# ATSAMA5D27 register map
Vendor: Microchip Technology Inc.; File version: 1.0
CPU: CA5 r0p1, little endian, no MPU, no FPU, 4 interrupt priority bits
Address unit: 32 bits
Registers are 32-bit, read-write, reset 0x0 unless marked. A register's access mark holds for its fields unless they carry their own. Offsets are from the block's base; [hi:lo] are bit positions.

## SDMMC0 — Secure Digital MultiMedia Card Controller
Base 0xA0000000
Same registers: SDMMC1 0xB0000000
0x00 SSAR — SDMA System Address / Argument 2 Register
  [31:0] ADDR — SDMA System Address
  [31:0] ARG2 — Argument 2
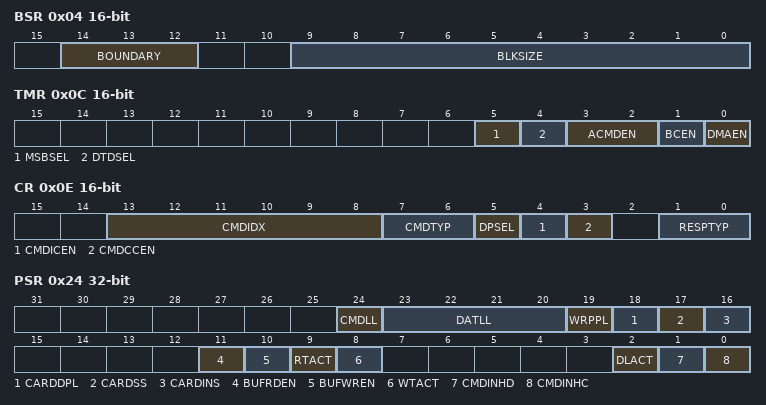
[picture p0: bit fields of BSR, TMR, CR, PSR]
0x04 BSR 16-bit — Block Size Register
  [14:12] BOUNDARY — SDMA Buffer Boundary
    0=_4K (4-Kbyte boundary); 1=_8K (8-Kbyte boundary); 2=_16K (16-Kbyte boundary); 3=_32K (32-Kbyte boundary); 4=_64K (64-Kbyte boundary); 5=_128K (128-Kbyte boundary); 6=256-Kbyte boundary; 7=_512K (512-Kbyte boundary)
  [9:0] BLKSIZE — Transfer Block Size
0x06 BCR 16-bit — Block Count Register
  [15:0] BLKCNT — Block Count for Current Transfer
0x08 ARG1R — Argument 1 Register
  [31:0] ARG1 — Argument 1
0x0C TMR 16-bit — Transfer Mode Register
  [5] MSBSEL — Multi/Single Block Selection
  [4] DTDSEL — Data Transfer Direction Selection
    0=WRITE (Writes data from the SDMMC to the device.); 1=READ (Reads data from the device to the SDMMC.)
  [3:2] ACMDEN — Auto Command Enable
    0=DISABLED (Auto Command Disabled); 1=CMD12 (Auto CMD12 Enabled); 2=CMD23 (Auto CMD23 Enabled)
  [1] BCEN — Block Count Enable
    0=DISABLED (Block count is disabled.); 1=ENABLED (Block count is enabled.)
  [0] DMAEN — DMA Enable
    0=DISABLED (DMA functionality is disabled.); 1=ENABLED (DMA functionality is enabled.)
0x0E CR 16-bit — Command Register
  [13:8] CMDIDX — Command Index
  [7:6] CMDTYP — Command Type
    0=NORMAL (Other commands); 1=SUSPEND (CMD52 to write "Bus Suspend" in the Card Common Control Registers (CCCR) (for SDIO only)); 2=RESUME (CMD52 to write "Function Select" in the Card Common Control Registers (CCCR) (for SDIO only)); 3=ABORT (CMD12, CMD52 to write "I/O Abort" in the Card Common Control Registers (CCCR) (for SDIO only))
  [5] DPSEL — Data Present Select
  [4] CMDICEN — Command Index Check Enable
    0=DISABLED (The Command Index Check is disabled.); 1=ENABLED (The Command Index Check is enabled.)
  [3] CMDCCEN — Command CRC Check Enable
    0=DISABLED (The Command CRC Check is disabled.); 1=ENABLED (The Command CRC Check is enabled.)
  [1:0] RESPTYP — Response Type
    0=NORESP (No Response); 1=RL136 (Response Length 136); 2=RL48 (Response Length 48); 3=RL48BUSY (Response Length 48 with Busy)
0x10 RR ro — Response Register
  [31:0] CMDRESP rw — Command Response
0x20 BDPR — Buffer Data Port Register
  [31:0] BUFDATA — Buffer Data
0x24 PSR ro — Present State Register
  [24] CMDLL rw — CMD Line Level
  [23:20] DATLL rw — DAT[3:0] Line Level
  [19] WRPPL rw — Write Protect Pin Level
  [18] CARDDPL rw — Card Detect Pin Level
  [17] CARDSS rw — Card State Stable
  [16] CARDINS rw — Card Inserted
  [11] BUFRDEN rw — Buffer Read Enable
  [10] BUFWREN rw — Buffer Write Enable
  [9] RTACT rw — Read Transfer Active
  [8] WTACT rw — Write Transfer Active
  [2] DLACT rw — DAT Line Active
  [1] CMDINHD rw — Command Inhibit (DAT)
  [0] CMDINHC rw — Command Inhibit (CMD)
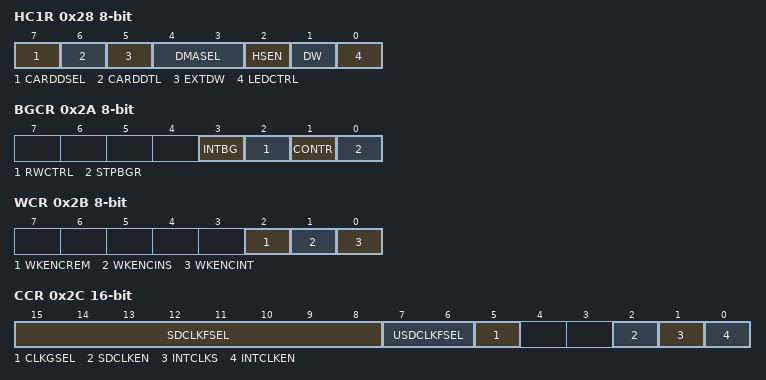
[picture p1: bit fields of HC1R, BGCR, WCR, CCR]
0x28 HC1R 8-bit — Host Control 1 Register
  [7] CARDDSEL — Card Detect Signal Selection
  [6] CARDDTL — Card Detect Test Level
  [5] EXTDW — Extended Data Width
  [4:3] DMASEL — DMA Select
    0=SDMA (SDMA is selected); 2=ADMA32 (32-bit Address ADMA2 is selected)
  [2] HSEN — High Speed Enable
  [1] DW — Data Width
    0=_1_BIT (1-bit mode.); 1=_4_BIT (4-bit mode.)
  [0] LEDCTRL — LED Control
    0=OFF (LED off.); 1=ON (LED on.)
0x29 PCR 8-bit — Power Control Register
  [0] SDBPWR — SD Bus Power
0x2A BGCR 8-bit — Block Gap Control Register
  [3] INTBG — Interrupt at Block Gap
    0=DISABLED (Interrupt detection disabled.); 1=ENABLED (Interrupt detection enabled.)
  [2] RWCTRL — Read Wait Control
  [1] CONTR — Continue Request
  [0] STPBGR — Stop At Block Gap Request
0x2B WCR 8-bit — Wakeup Control Register
  [all] fields
    0=DISABLED (Wakeup Event disabled.); 1=ENABLED (Wakeup Event enabled.)
  [2] WKENCREM — Wakeup Event Enable on Card Removal
  [1] WKENCINS — Wakeup Event Enable on Card Insertion
  [0] WKENCINT — Wakeup Event Enable on Card Interrupt
0x2C CCR 16-bit — Clock Control Register
  [15:8] SDCLKFSEL — SDCLK Frequency Select
  [7:6] USDCLKFSEL — Upper Bits of SDCLK Frequency Select
  [5] CLKGSEL — Clock Generator Select
  [2] SDCLKEN — SD Clock Enable
  [1] INTCLKS — Internal Clock Stable
  [0] INTCLKEN — Internal Clock Enable
0x2E TCR 8-bit — Timeout Control Register
  [3:0] DTCVAL — Data Timeout Counter Value
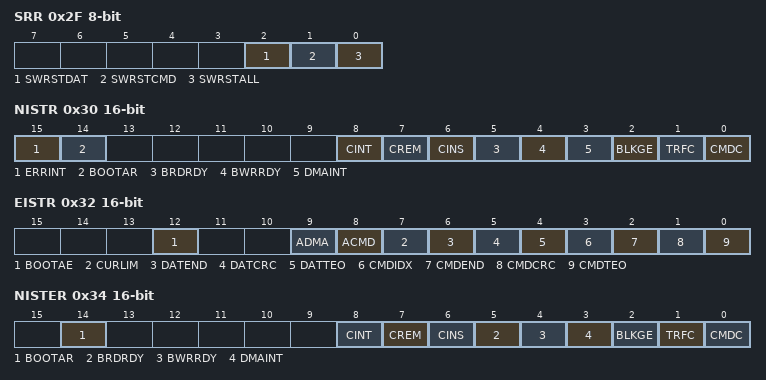
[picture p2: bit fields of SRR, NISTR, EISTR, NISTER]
0x2F SRR 8-bit — Software Reset Register
  [2] SWRSTDAT — Software reset for DAT line
  [1] SWRSTCMD — Software reset for CMD line
  [0] SWRSTALL — Software reset for All
0x30 NISTR 16-bit — Normal Interrupt Status Register
  [15] ERRINT — Error Interrupt
  [14] BOOTAR — Boot Acknowledge Received
  [8] CINT — Card Interrupt
  [7] CREM — Card Removal
  [6] CINS — Card Insertion
  [5] BRDRDY — Buffer Read Ready
  [4] BWRRDY — Buffer Write Ready
  [3] DMAINT — DMA Interrupt
  [2] BLKGE — Block Gap Event
  [1] TRFC — Transfer Complete
  [0] CMDC — Command Complete
0x32 EISTR 16-bit — Error Interrupt Status Register
  [12] BOOTAE — Boot Acknowledge Error
  [9] ADMA — ADMA Error
  [8] ACMD — Auto CMD Error
  [7] CURLIM — Current Limit Error
  [6] DATEND — Data End Bit Error
  [5] DATCRC — Data CRC Error
  [4] DATTEO — Data Timeout error
  [3] CMDIDX — Command Index Error
  [2] CMDEND — Command End Bit Error
  [1] CMDCRC — Command CRC Error
  [0] CMDTEO — Command Timeout Error
0x34 NISTER 16-bit — Normal Interrupt Status Enable Register
  [14] BOOTAR — Boot Acknowledge Received Status Enable
    0=MASKED (The BOOTAR status flag in SDMMC_NISTR is masked.); 1=ENABLED (The BOOTAR status flag in SDMMC_NISTR is enabled.)
  [8] CINT — Card Interrupt Status Enable
    0=MASKED (The CINT status flag in SDMMC_NISTR is masked.); 1=ENABLED (The CINT status flag in SDMMC_NISTR is enabled.)
  [7] CREM — Card Removal Status Enable
    0=MASKED (The CREM status flag in SDMMC_NISTR is masked.); 1=ENABLED (The CREM status flag in SDMMC_NISTR is enabled.)
  [6] CINS — Card Insertion Status Enable
    0=MASKED (The CINS status flag in SDMMC_NISTR is masked.); 1=ENABLED (The CINS status flag in SDMMC_NISTR is enabled.)
  [5] BRDRDY — Buffer Read Ready Status Enable
    0=MASKED (The BRDRDY status flag in SDMMC_NISTR is masked.); 1=ENABLED (The BRDRDY status flag in SDMMC_NISTR is enabled.)
  [4] BWRRDY — Buffer Write Ready Status Enable
    0=MASKED (The BWRRDY status flag in SDMMC_NISTR is masked.); 1=ENABLED (The BWRRDY status flag in SDMMC_NISTR is enabled.)
  [3] DMAINT — DMA Interrupt Status Enable
    0=MASKED (The DMAINT status flag in SDMMC_NISTR is masked.); 1=ENABLED (The DMAINT status flag in SDMMC_NISTR is enabled.)
  [2] BLKGE — Block Gap Event Status Enable
    0=MASKED (The BLKGE status flag in SDMMC_NISTR is masked.); 1=ENABLED (The BLKGE status flag in SDMMC_NISTR is enabled.)
  [1] TRFC — Transfer Complete Status Enable
    0=MASKED (The TRFC status flag in SDMMC_NISTR is masked.); 1=ENABLED (The TRFC status flag in SDMMC_NISTR is enabled.)
  [0] CMDC — Command Complete Status Enable
    0=MASKED (The CMDC status flag in SDMMC_NISTR is masked.); 1=ENABLED (The CMDC status flag in SDMMC_NISTR is enabled.)
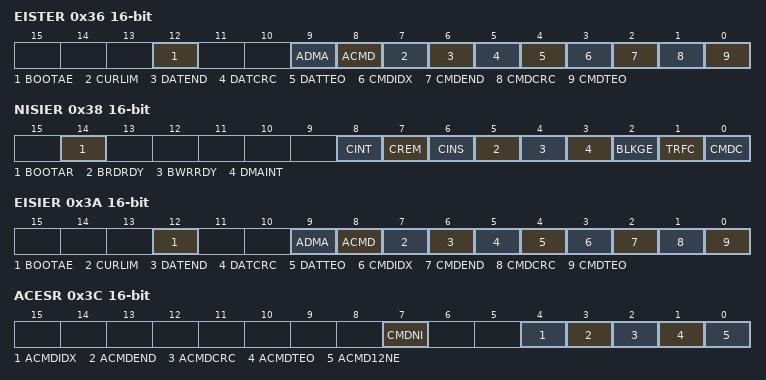
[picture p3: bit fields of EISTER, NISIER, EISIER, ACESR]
0x36 EISTER 16-bit — Error Interrupt Status Enable Register
  [12] BOOTAE — Boot Acknowledge Error Status Enable
    0=MASKED (The BOOTAE status flag in SDMMC_EISTR is masked.); 1=ENABLED (The BOOTAE status flag in SDMMC_EISTR is enabled.)
  [9] ADMA — ADMA Error Status Enable
    0=MASKED (The ADMA status flag in SDMMC_EISTR is masked.); 1=ENABLED (The ADMA status flag in SDMMC_EISTR is enabled.)
  [8] ACMD — Auto CMD Error Status Enable
    0=MASKED (The ACMD status flag in SDMMC_EISTR is masked.); 1=ENABLED (The ACMD status flag in SDMMC_EISTR is enabled.)
  [7] CURLIM — Current Limit Error Status Enable
    0=MASKED (The CURLIM status flag in SDMMC_EISTR is masked.); 1=ENABLED (The CURLIM status flag in SDMMC_EISTR is enabled.)
  [6] DATEND — Data End Bit Error Status Enable
    0=MASKED (The DATEND status flag in SDMMC_EISTR is masked.); 1=ENABLED (The DATEND status flag in SDMMC_EISTR is enabled.)
  [5] DATCRC — Data CRC Error Status Enable
    0=MASKED (The DATCRC status flag in SDMMC_EISTR is masked.); 1=ENABLED (The DATCRC status flag in SDMMC_EISTR is enabled.)
  [4] DATTEO — Data Timeout Error Status Enable
    0=MASKED (The DATTEO status flag in SDMMC_EISTR is masked.); 1=ENABLED (The DATTEO status flag in SDMMC_EISTR is enabled.)
  [3] CMDIDX — Command Index Error Status Enable
    0=MASKED (The CMDIDX status flag in SDMMC_EISTR is masked.); 1=ENABLED (The CMDIDX status flag in SDMMC_EISTR is enabled.)
  [2] CMDEND — Command End Bit Error Status Enable
    0=MASKED (The CMDEND status flag in SDMMC_EISTR is masked.); 1=ENABLED (The CMDEND status flag in SDMMC_EISTR is enabled.)
  [1] CMDCRC — Command CRC Error Status Enable
    0=MASKED (The CMDCRC status flag in SDMMC_EISTR is masked.); 1=ENABLED (The CMDCRC status flag in SDMMC_EISTR is enabled.)
  [0] CMDTEO — Command Timeout Error Status Enable
    0=MASKED (The CMDTEO status flag in SDMMC_EISTR is masked.); 1=ENABLED (The CMDTEO status flag in SDMMC_EISTR is enabled.)
0x38 NISIER 16-bit — Normal Interrupt Signal Enable Register
  [14] BOOTAR — Boot Acknowledge Received Signal Enable
    0=MASKED (No interrupt is generated when the BOOTAR status rises in SDMMC_NISTR.); 1=ENABLED (An interrupt is generated when the BOOTAR status rises in SDMMC_NISTR.)
  [8] CINT — Card Interrupt Signal Enable
    0=MASKED (No interrupt is generated when the CINT status rises in SDMMC_NISTR.); 1=ENABLED (An interrupt is generated when the CINT status rises in SDMMC_NISTR.)
  [7] CREM — Card Removal Signal Enable
    0=MASKED (No interrupt is generated when the CREM status rises in SDMMC_NISTR.); 1=ENABLED (An interrupt is generated when the CREM status rises in SDMMC_NISTR.)
  [6] CINS — Card Insertion Signal Enable
    0=MASKED (No interrupt is generated when the CINS status rises in SDMMC_NISTR.); 1=ENABLED (An interrupt is generated when the CINS status rises in SDMMC_NISTR.)
  [5] BRDRDY — Buffer Read Ready Signal Enable
    0=MASKED (No interrupt is generated when the BRDRDY status rises in SDMMC_NISTR.); 1=ENABLED (An interrupt is generated when the BRDRDY status rises in SDMMC_NISTR.)
  [4] BWRRDY — Buffer Write Ready Signal Enable
    0=MASKED (No interrupt is generated when the BWRRDY status rises in SDMMC_NISTR.); 1=ENABLED (An interrupt is generated when the BWRRDY status rises in SDMMC_NISTR.)
  [3] DMAINT — DMA Interrupt Signal Enable
    0=MASKED (No interrupt is generated when the DMAINT status rises in SDMMC_NISTR.); 1=ENABLED (An interrupt is generated when the DMAINT status rises in SDMMC_NISTR.)
  [2] BLKGE — Block Gap Event Signal Enable
    0=MASKED (No interrupt is generated when the BLKGE status rises in SDMMC_NISTR.); 1=ENABLED (An interrupt is generated when the BLKGE status rises in SDMMC_NISTR.)
  [1] TRFC — Transfer Complete Signal Enable
    0=MASKED (No interrupt is generated when the TRFC status rises in SDMMC_NISTR.); 1=ENABLED (An interrupt is generated when the TRFC status rises in SDMMC_NISTR.)
  [0] CMDC — Command Complete Signal Enable
    0=MASKED (No interrupt is generated when the CMDC status rises in SDMMC_NISTR.); 1=ENABLED (An interrupt is generated when the CMDC status rises in SDMMC_NISTR.)
0x3A EISIER 16-bit — Error Interrupt Signal Enable Register
  [12] BOOTAE — Boot Acknowledge Error Signal Enable
    0=MASKED (No interrupt is generated when the BOOTAE status rises in SDMMC_EISTR.); 1=ENABLED (An interrupt is generated when the BOOTAE status rises in SDMMC_EISTR.)
  [9] ADMA — ADMA Error Signal Enable
    0=MASKED (No interrupt is generated when the ADMA status rises in SDMMC_EISTR.); 1=ENABLED (An interrupt is generated when the ADMA status rises in SDMMC_EISTR.)
  [8] ACMD — Auto CMD Error Signal Enable
    0=MASKED (No interrupt is generated when the ACMD status rises in SDMMC_EISTR.); 1=ENABLED (An interrupt is generated when the ACMD status rises in SDMMC_EISTR.)
  [7] CURLIM — Current Limit Error Signal Enable
    0=MASKED (No interrupt is generated when the CURLIM status rises in SDMMC_EISTR.); 1=ENABLED (An interrupt is generated when the CURLIM status rises in SDMMC_EISTR.)
  [6] DATEND — Data End Bit Error Signal Enable
    0=MASKED (No interrupt is generated when the DATEND status rises in SDMMC_EISTR.); 1=ENABLED (An interrupt is generated when the DATEND status rises in SDMMC_EISTR.)
  [5] DATCRC — Data CRC Error Signal Enable
    0=MASKED (No interrupt is generated when the DATCRC status rises in SDMMC_EISTR.); 1=ENABLED (An interrupt is generated when the DATCRC status rises in SDMMC_EISTR.)
  [4] DATTEO — Data Timeout Error Signal Enable
    0=MASKED (No interrupt is generated when the DATTEO status rises in SDMMC_EISTR.); 1=ENABLED (An interrupt is generated when the DATTEO status rises in SDMMC_EISTR.)
  [3] CMDIDX — Command Index Error Signal Enable
    0=MASKED (No interrupt is generated when the CMDIDX status rises in SDMMC_EISTR.); 1=ENABLED (An interrupt is generated when the CMDIDX status rises in SDMMC_EISTR.)
  [2] CMDEND — Command End Bit Error Signal Enable
    0=MASKED (No interrupt is generated when the CMDEND status rises in SDMMC_EISTR.); 1=ENABLED (An interrupt is generated when the CMDEND status rises in SDMMC_EISTR.)
  [1] CMDCRC — Command CRC Error Signal Enable
    0=MASKED (No interrupt is generated when the CDMCRC status rises in SDMMC_EISTR.); 1=ENABLED (An interrupt is generated when the CMDCRC status rises in SDMMC_EISTR.)
  [0] CMDTEO — Command Timeout Error Signal Enable
    0=MASKED (No interrupt is generated when the CMDTEO status rises in SDMMC_EISTR.); 1=ENABLED (An interrupt is generated when the CMDTEO status rises in SDMMC_EISTR.)
0x3C ACESR 16-bit ro — Auto CMD Error Status Register
  [7] CMDNI rw — Command Not Issued by Auto CMD12 Error
  [4] ACMDIDX rw — Auto CMD Index Error
  [3] ACMDEND rw — Auto CMD End Bit Error
  [2] ACMDCRC rw — Auto CMD CRC Error
  [1] ACMDTEO rw — Auto CMD Timeout Error
  [0] ACMD12NE rw — Auto CMD12 Not Executed
0x3E HC2R 16-bit — Host Control 2 Register
  [15] PVALEN — Preset Value Enable
  [14] ASINTEN — Asynchronous Interrupt Enable
  [7] SCLKSEL — Sampling Clock Select
  [6] EXTUN — Execute Tuning
  [5:4] DRVSEL — Driver Strength Select
    0=TYPEB (Driver Type B is selected (Default)); 1=TYPEA (Driver Type A is selected); 2=TYPEC (Driver Type C is selected); 3=TYPED (Driver Type D is selected)
  [3] VS18EN — 1.8V Signaling Enable
  [3:0] HS200EN — HS200 Mode Enable
  [2:0] UHSMS — UHS Mode Select
    0=SDR12 (UHS SDR12 Mode); 1=SDR25 (UHS SDR25 Mode); 2=SDR50 (UHS SDR50 Mode); 3=SDR104 (UHS SDR104 Mode); 4=DDR50 (UHS DDR50 Mode)
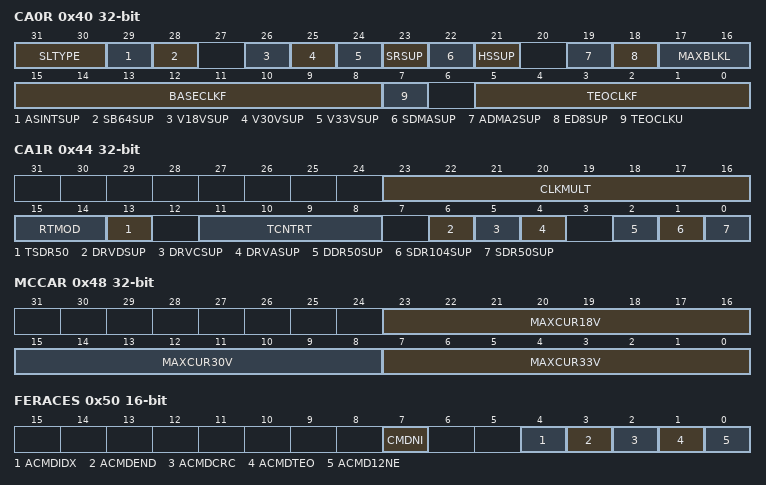
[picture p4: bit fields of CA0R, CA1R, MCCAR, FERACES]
0x40 CA0R ro — Capabilities 0 Register
  [31:30] SLTYPE rw — Slot Type
  [29] ASINTSUP rw — Asynchronous Interrupt Support
  [28] SB64SUP rw — 64-Bit System Bus Support
  [26] V18VSUP rw — Voltage Support 1.8V
  [25] V30VSUP rw — Voltage Support 3.0V
  [24] V33VSUP rw — Voltage Support 3.3V
  [23] SRSUP rw — Suspend/Resume Support
  [22] SDMASUP rw — SDMA Support
  [21] HSSUP rw — High Speed Support
  [19] ADMA2SUP rw — ADMA2 Support
  [18] ED8SUP rw — 8-Bit Support for Embedded Device
  [17:16] MAXBLKL rw — Max Block Length
    0=512 bytes; 1=1024 bytes; 2=2048 bytes
  [15:8] BASECLKF rw — Base Clock Frequency
  [7] TEOCLKU rw — Timeout Clock Unit
  [5:0] TEOCLKF rw — Timeout Clock Frequency
0x44 CA1R — Capabilities 1 Register
  [23:16] CLKMULT — Clock Multiplier
  [15:14] RTMOD — Retuning Modes
    0=MODE1 (Timer); 1=MODE2 (Timer and Retuning Request); 2=MODE3 (Auto Retuning (for transfer) Timer and Retuning Request)
  [13] TSDR50 — Use Tuning for SDR50
  [11:8] TCNTRT — Timer Count For Retuning
  [6] DRVDSUP — Driver Type D Support
  [5] DRVCSUP — Driver Type C Support
  [4] DRVASUP — Driver Type A Support
  [2] DDR50SUP — DDR50 Support
  [1] SDR104SUP — SDR104 Support
  [0] SDR50SUP — SDR50 Support
0x48 MCCAR — Maximum Current Capabilities Register
  [23:16] MAXCUR18V — Maximum Current for 1.8V
  [15:8] MAXCUR30V — Maximum Current for 3.0V
  [7:0] MAXCUR33V — Maximum Current for 3.3V
0x50 FERACES 16-bit wo — Force Event Register for Auto CMD Error Status
  [7] CMDNI rw — Force Event for Command Not Issued by Auto CMD12 Error
  [4] ACMDIDX rw — Force Event for Auto CMD Index Error
  [3] ACMDEND rw — Force Event for Auto CMD End Bit Error
  [2] ACMDCRC rw — Force Event for Auto CMD CRC Error
  [1] ACMDTEO rw — Force Event for Auto CMD Timeout Error
  [0] ACMD12NE rw — Force Event for Auto CMD12 Not Executed
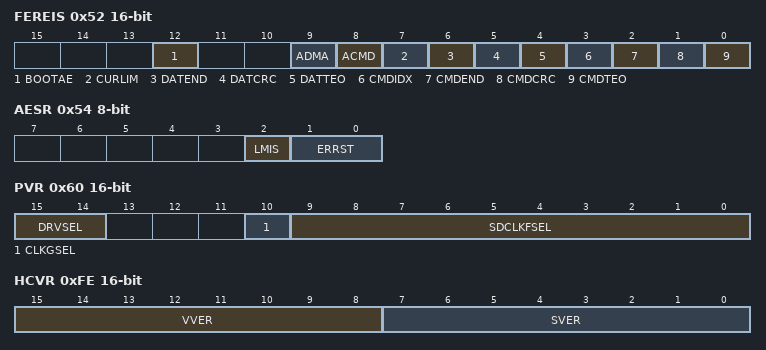
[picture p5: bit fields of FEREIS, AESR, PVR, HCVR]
0x52 FEREIS 16-bit wo — Force Event Register for Error Interrupt Status
  [12] BOOTAE rw — Force Event for Boot Acknowledge Error
  [9] ADMA rw — Force Event for ADMA Error
  [8] ACMD rw — Force Event for Auto CMD Error
  [7] CURLIM rw — Force Event for Current Limit Error
  [6] DATEND rw — Force Event for Data End Bit Error
  [5] DATCRC rw — Force Event for Data CRC error
  [4] DATTEO rw — Force Event for Data Timeout error
  [3] CMDIDX rw — Force Event for Command Index Error
  [2] CMDEND rw — Force Event for Command End Bit Error
  [1] CMDCRC rw — Force Event for Command CRC Error
  [0] CMDTEO rw — Force Event for Command Timeout Error
0x54 AESR 8-bit ro — ADMA Error Status Register
  [2] LMIS rw — ADMA Length Mismatch Error
  [1:0] ERRST rw — ADMA Error State
0x58 ASAR0 — ADMA System Address Register 0
  [31:0] ADMASA — ADMA System Address
0x60 PVR 16-bit — Preset Value Register 0 (for initialization)
  [15:14] DRVSEL — Driver Strength Select
  [10] CLKGSEL — Clock Generator Select
  [9:0] SDCLKFSEL — SDCLK Frequency Select
0xFC SISR 16-bit ro — Slot Interrupt Status Register
  [1:0] INTSSL rw — Interrupt Signal for Each Slot
0xFE HCVR 16-bit ro — Host Controller Version Register
  [15:8] VVER rw — Vendor Version Number
  [7:0] SVER rw — Specification Version Number
0x200 APSR ro — Additional Present State Register
  [3:0] HDATLL rw — DAT[7:4] High Line Level
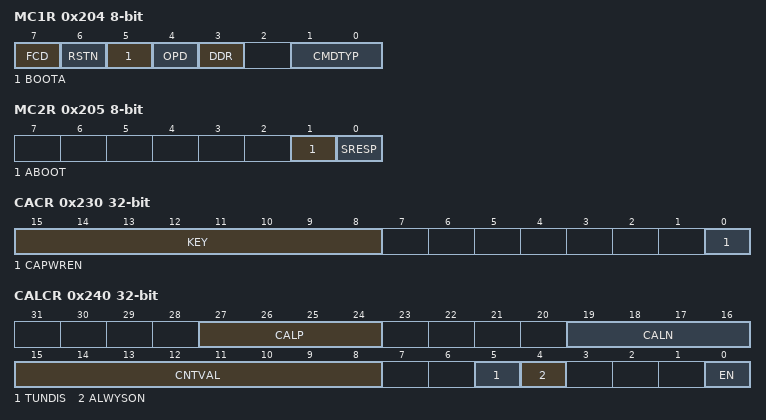
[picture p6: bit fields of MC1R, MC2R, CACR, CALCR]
0x204 MC1R 8-bit — e.MMC Control 1 Register
  [7] FCD — e.MMC Force Card Detect
  [6] RSTN — e.MMC Reset Signal
  [5] BOOTA — e.MMC Boot Acknowledge Enable
  [4] OPD — e.MMC Open Drain Mode
  [3] DDR — e.MMC HSDDR Mode
  [1:0] CMDTYP — e.MMC Command Type
    0=NORMAL (The command is not an e.MMC specific command.); 1=WAITIRQ (This bit must be set to 1 when the e.MMC is in Interrupt mode (CMD40). Refer to "Interrupt Mode" in the "Embedded MultiMedia Card (e.MMC) Electrical Standard 4.51" .); 2=STREAM (This bit must be set to 1 in the case of Stream Read(CMD11) or Stream Write (CMD20). Only effective for e.MMC up to revision 4.41.); 3=BOOT (Starts a Boot Operation mode at the next write to SDMMC_CR. Boot data are read directly from e.MMC device.)
0x205 MC2R 8-bit wo — e.MMC Control 2 Register
  [1] ABOOT rw — e.MMC Abort Boot
  [0] SRESP rw — e.MMC Abort Wait IRQ
0x208 ACR — AHB Control Register
  [1:0] BMAX — AHB Maximum Burst
    0=INCR16 (The maximum burst size is INCR16.); 1=INCR8 (The maximum burst size is INCR8.); 2=INCR4 (The maximum burst size is INCR4.); 3=SINGLE (Only SINGLE transfers are performed.)
0x20C CC2R — Clock Control 2 Register
  [0] FSDCLKD — Force SDCLK Disabled
0x210 RTC1R 8-bit — Retuning Timer Control 1 Register
  [0] TMREN — Retuning Timer Enable
    0=DISABLED (The retuning timer is disabled.); 1=ENABLED (The retuning timer is enabled.)
0x211 RTC2R 8-bit wo — Retuning Timer Control 2 Register
  [0] RLD rw — Retuning Timer Reload
0x214 RTCVR — Retuning Timer Counter Value Register
  [3:0] TCVAL — Retuning Timer Counter Value
0x218 RTISTER 8-bit — Retuning Timer Interrupt Status Enable Register
  [0] TEVT — Retuning Timer Event
    0=MASKED (The TEVT status flag in SDMMC_RTISTR is masked.); 1=ENABLED (The TEVT status flag in SDMMC_RTISTR is enabled.)
0x219 RTISIER 8-bit — Retuning Timer Interrupt Signal Enable Register
  [0] TEVT — Retuning Timer Event
    0=MASKED (No interrupt is generated when the TEVT status rises in SDMMC_RTISTR.); 1=ENABLED (An interrupt is generated when the TEVT status rises in SDMMC_RTISTR.)
0x21C RTISTR 8-bit — Retuning Timer Interrupt Status Register
  [0] TEVT — Retuning Timer Event
0x21D RTSSR 8-bit ro — Retuning Timer Status Slots Register
  [1:0] TEVTSLOT rw — Retuning Timer Event Slots
0x220 TUNCR — Tuning Control Register
  [0] SMPLPT — Sampling Point
0x230 CACR — Capabilities Control Register
  [15:8] KEY
  [0] CAPWREN — Capabilities Write Enable
0x240 CALCR — Calibration Control Register
  [27:24] CALP — Calibration P Status
  [19:16] CALN — Calibration N Status
  [15:8] CNTVAL — Calibration Counter Value
  [5] TUNDIS — Calibration During Tuning Disabled
  [4] ALWYSON — Calibration Analog Always ON
  [0] EN — PADs Calibration Enable
